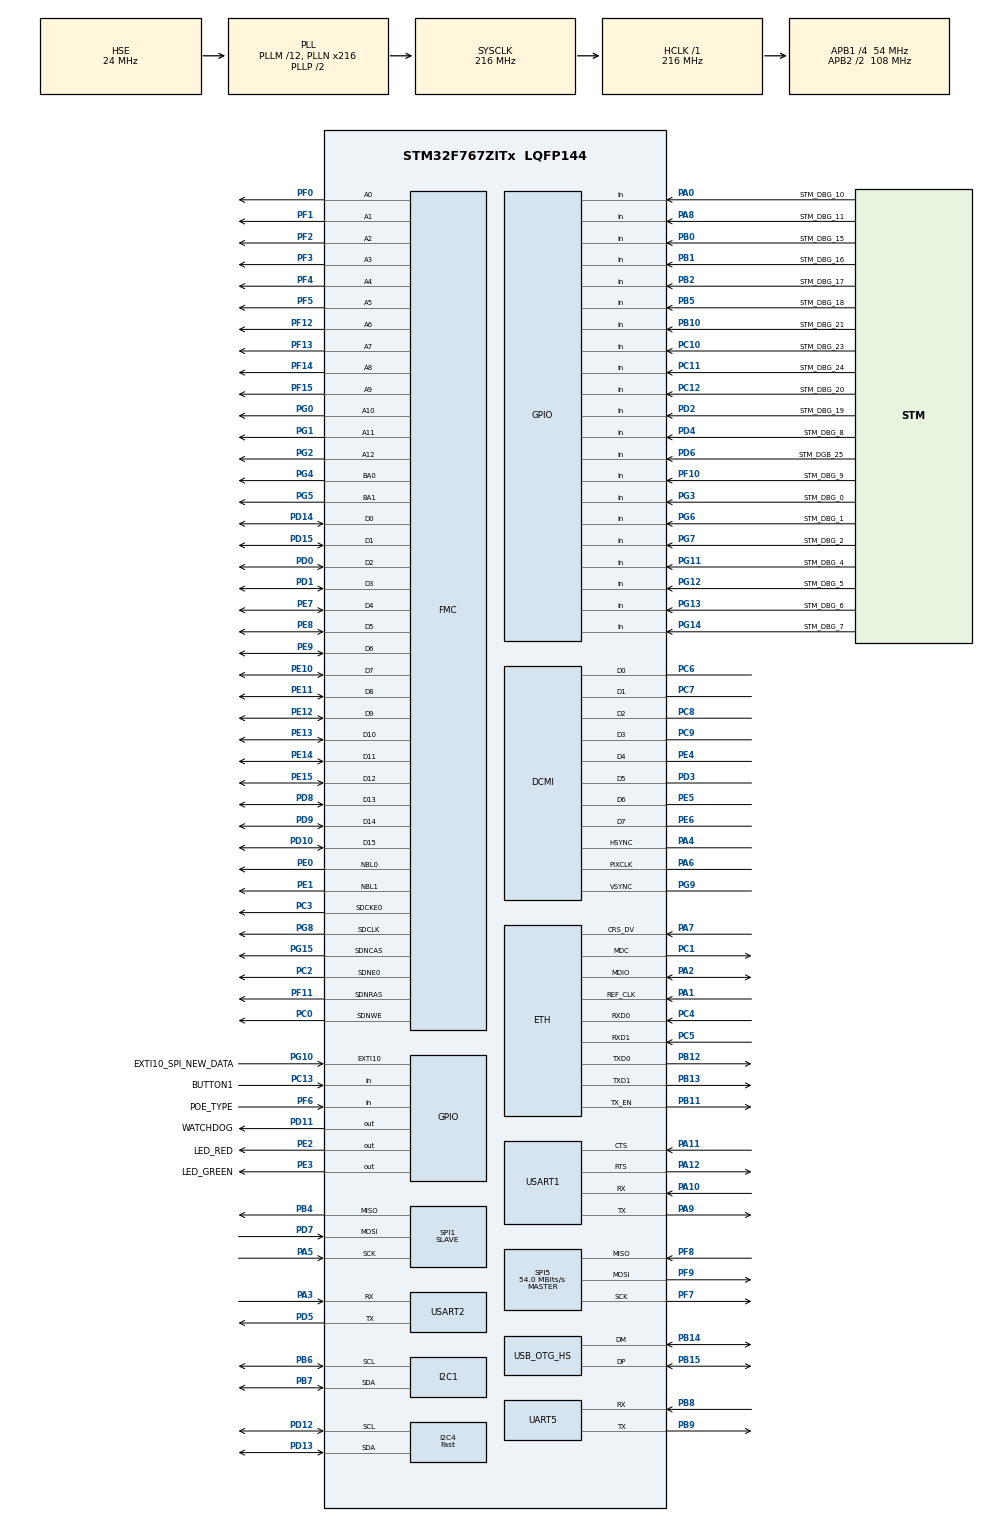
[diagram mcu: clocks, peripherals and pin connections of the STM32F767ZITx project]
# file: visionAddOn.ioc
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DCMI.CaptureRate=DCMI_CR_ALL_FRAME
DCMI.HSPolarity=DCMI_HSPOLARITY_LOW
DCMI.JPEGMode=DCMI_JPEG_DISABLE
DCMI.PCKPolarity=DCMI_PCKPOLARITY_RISING
DCMI.VSPolarity=DCMI_VSPOLARITY_LOW
Dma.DCMI.0.Direction=DMA_PERIPH_TO_MEMORY
Dma.DCMI.0.FIFOMode=DMA_FIFOMODE_DISABLE
Dma.DCMI.0.Instance=DMA2_Stream1
Dma.DCMI.0.MemDataAlignment=DMA_MDATAALIGN_WORD
Dma.DCMI.0.MemInc=DMA_MINC_ENABLE
Dma.DCMI.0.Mode=DMA_CIRCULAR
Dma.DCMI.0.PeriphDataAlignment=DMA_PDATAALIGN_WORD
Dma.DCMI.0.PeriphInc=DMA_PINC_DISABLE
Dma.DCMI.0.Priority=DMA_PRIORITY_HIGH
Dma.Request0=DCMI
Dma.Request1=USART2_RX
Dma.Request2=SPI1_RX
Dma.SPI1_RX.2.Direction=DMA_PERIPH_TO_MEMORY
Dma.SPI1_RX.2.FIFOMode=DMA_FIFOMODE_DISABLE
Dma.SPI1_RX.2.Instance=DMA2_Stream0
Dma.SPI1_RX.2.MemDataAlignment=DMA_MDATAALIGN_BYTE
Dma.SPI1_RX.2.MemInc=DMA_MINC_ENABLE
Dma.SPI1_RX.2.Mode=DMA_NORMAL
Dma.SPI1_RX.2.PeriphDataAlignment=DMA_PDATAALIGN_BYTE
Dma.SPI1_RX.2.PeriphInc=DMA_PINC_DISABLE
Dma.SPI1_RX.2.Priority=DMA_PRIORITY_MEDIUM
Dma.USART2_RX.1.Direction=DMA_PERIPH_TO_MEMORY
Dma.USART2_RX.1.FIFOMode=DMA_FIFOMODE_DISABLE
Dma.USART2_RX.1.Instance=DMA1_Stream5
Dma.USART2_RX.1.MemDataAlignment=DMA_MDATAALIGN_BYTE
Dma.USART2_RX.1.MemInc=DMA_MINC_ENABLE
Dma.USART2_RX.1.Mode=DMA_NORMAL
Dma.USART2_RX.1.PeriphDataAlignment=DMA_PDATAALIGN_BYTE
Dma.USART2_RX.1.PeriphInc=DMA_PINC_DISABLE
Dma.USART2_RX.1.Priority=DMA_PRIORITY_MEDIUM
ETH.MediaInterface=HAL_ETH_RMII_MODE
FMC.CASLatency1=FMC_SDRAM_CAS_LATENCY_3
FMC.ColumnBitsNumber1=FMC_SDRAM_COLUMN_BITS_NUM_9
FMC.ExitSelfRefreshDelay1=14
FMC.LoadToActiveDelay1=2
FMC.RCDDelay1=3
FMC.RPDelay1=3
FMC.RPDelay2=3
FMC.ReadBurst1=FMC_SDRAM_RBURST_ENABLE
FMC.ReadBurst2=FMC_SDRAM_RBURST_ENABLE
FMC.ReadPipeDelay1=FMC_SDRAM_RPIPE_DELAY_0
FMC.RowCycleDelay1=10
FMC.RowCycleDelay2=10
FMC.SDClockPeriod1=FMC_SDRAM_CLOCK_PERIOD_2
FMC.SDClockPeriod2=FMC_SDRAM_CLOCK_PERIOD_2
FREERTOS.Tasks01=networkTask,24,1024,StartNetworkTask,Default,NULL,Static,networkTaskBuffer,networkTaskControlBlock;blobDetectorTas,24,512,StartBlobDetectorTask,Default,NULL,Static,blobDetectorBuffer,blobDetectorControlBlock;statsTask,8,256,StartStatsTask,Default,NULL,Static,statsTaskBuffer,statsTaskControlBlock
FREERTOS.configCHECK_FOR_STACK_OVERFLOW=2
FREERTOS.configENABLE_FPU=1
FREERTOS.configGENERATE_RUN_TIME_STATS=1
FREERTOS.configRECORD_STACK_HIGH_ADDRESS=1
FREERTOS.configUSE_MALLOC_FAILED_HOOK=1
FREERTOS.configUSE_NEWLIB_REENTRANT=1
I2C1.Timing=0x20404768
I2C4.I2C_Speed_Mode=I2C_Fast
I2C4.Timing=0x6000030D
LWIP.BSP.number=1
LWIP.DEFAULT_RAW_RECVMBOX_SIZE=6
LWIP.DEFAULT_THREAD_STACKSIZE=1024
LWIP.GATEWAY_ADDRESS=010.000.000.001
LWIP.IP_ADDRESS=010.000.000.001
LWIP.LWIP_DHCP=0
LWIP.LWIP_DISABLE_TCP_SANITY_CHECKS=0
LWIP.LWIP_PERF=1
LWIP.LWIP_RAM_HEAP_POINTER=0x30004000
LWIP.LWIP_STATS=1
LWIP.MEMP_NUM_TCP_PCB=2
LWIP.MEMP_NUM_UDP_PCB=2
LWIP.MEM_SIZE=8192
LWIP.NETMASK_ADDRESS=255.255.255.000
LWIP.SLIPIF_THREAD_STACKSIZE=1024
LWIP.SYS_LIGHTWEIGHT_PROT=1
LWIP.TCPIP_THREAD_STACKSIZE=2048
LWIP.Version=v2.1.2_Cube
LWIP0.BSP.STBoard=false
LWIP0.BSP.api=BSP_COMPONENT_DRIVER
LWIP0.BSP.component=LAN8742
LWIP0.BSP.instance=LAN8742
LWIP0.BSP.name=Driver_PHY
LWIP0.BSP.semaphore=S_LAN8742
LWIP0.BSP.solution=LAN8742
Mcu.Family=STM32F7
Mcu.Name=STM32F767ZITx
Mcu.Package=LQFP144
NVIC.DCMI_IRQn=true\:5\:0\:false\:false\:true\:true\:true\:true\:true
NVIC.DMA1_Stream5_IRQn=true\:5\:0\:false\:false\:true\:true\:false\:true\:true
NVIC.DMA2_Stream0_IRQn=true\:5\:0\:false\:false\:true\:true\:false\:true\:true
NVIC.DMA2_Stream1_IRQn=true\:5\:0\:false\:false\:true\:true\:false\:true\:true
NVIC.ETH_IRQn=true\:5\:0\:false\:false\:true\:true\:false\:true\:true
NVIC.EXTI15_10_IRQn=true\:5\:0\:false\:false\:true\:true\:true\:true\:true
NVIC.PriorityGroup=NVIC_PRIORITYGROUP_4
NVIC.TIM1_UP_TIM10_IRQn=true\:15\:0\:false\:false\:true\:false\:false\:true\:true
NVIC.TimeBase=TIM1_UP_TIM10_IRQn
NVIC.TimeBaseIP=TIM1
NVIC.USART2_IRQn=true\:5\:0\:false\:false\:true\:true\:true\:true\:true
PA0/WKUP.GPIO_Label=STM_DBG_10
PA0/WKUP.Signal=GPIO_Input
PA1.Mode=RMII
PA1.Signal=ETH_REF_CLK
PA10.Mode=Asynchronous
PA10.Signal=USART1_RX
PA11.Mode=CTS_RTS
PA11.Signal=USART1_CTS
PA12.Mode=CTS_RTS
PA12.Signal=USART1_RTS
PA13.GPIO_Label=TMS
PA13.Mode=Serial_Wire
PA13.Signal=SYS_JTMS-SWDIO
PA14.GPIO_Label=TCK
PA14.Mode=Serial_Wire
PA14.Signal=SYS_JTCK-SWCLK
PA15.Signal=SYS_JTDI
PA2.Mode=RMII
PA2.Signal=ETH_MDIO
PA3.Mode=Asynchronous
PA3.Signal=USART2_RX
PA4.Mode=Slave_8_bits_External_Synchro
PA4.Signal=DCMI_HSYNC
PA5.Mode=Full_Duplex_Slave
PA5.Signal=SPI1_SCK
PA6.Mode=Slave_8_bits_External_Synchro
PA6.Signal=DCMI_PIXCLK
PA7.Mode=RMII
PA7.Signal=ETH_CRS_DV
PA8.GPIO_Label=STM_DBG_11
PA8.Signal=GPIO_Input
PA9.Mode=Asynchronous
PA9.Signal=USART1_TX
PB0.GPIO_Label=STM_DBG_15
PB0.Signal=GPIO_Input
PB1.GPIO_Label=STM_DBG_16
PB1.Signal=GPIO_Input
PB10.GPIO_Label=STM_DBG_21
PB10.Signal=GPIO_Input
PB11.Mode=RMII
PB11.Signal=ETH_TX_EN
PB12.Mode=RMII
PB12.Signal=ETH_TXD0
PB13.Mode=RMII
PB13.Signal=ETH_TXD1
PB14.Mode=Device_Only_FS
PB14.Signal=USB_OTG_HS_DM
PB15.Mode=Device_Only_FS
PB15.Signal=USB_OTG_HS_DP
PB2.GPIO_Label=STM_DBG_17
PB2.Signal=GPIO_Input
PB3.GPIO_Label=SWO
PB3.Signal=SYS_JTDO-SWO
PB4.Mode=Full_Duplex_Slave
PB4.Signal=SPI1_MISO
PB5.GPIO_Label=STM_DBG_18
PB5.Signal=GPIO_Input
PB6.Mode=I2C
PB6.Signal=I2C1_SCL
PB7.Mode=I2C
PB7.Signal=I2C1_SDA
PB8.Mode=Asynchronous
PB8.Signal=UART5_RX
PB9.Mode=Asynchronous
PB9.Signal=UART5_TX
PC0.Signal=FMC_SDNWE
PC1.Mode=RMII
PC1.Signal=ETH_MDC
PC10.GPIO_Label=STM_DBG_23
PC10.Signal=GPIO_Input
PC11.GPIO_Label=STM_DBG_24
PC11.Signal=GPIO_Input
PC12.GPIO_Label=STM_DBG_20
PC12.Signal=GPIO_Input
PC13.GPIO_Label=BUTTON1
PC13.Signal=GPIO_Input
PC14/OSC32_IN.Mode=LSE-External-Oscillator
PC14/OSC32_IN.Signal=RCC_OSC32_IN
PC15/OSC32_OUT.Mode=LSE-External-Oscillator
PC15/OSC32_OUT.Signal=RCC_OSC32_OUT
PC2.Mode=SdramChipSelect1_1
PC2.Signal=FMC_SDNE0
PC3.Mode=SdramChipSelect1_1
PC3.Signal=FMC_SDCKE0
PC4.Mode=RMII
PC4.Signal=ETH_RXD0
PC5.Mode=RMII
PC5.Signal=ETH_RXD1
PC6.Mode=Slave_8_bits_External_Synchro
PC6.Signal=DCMI_D0
PC7.Mode=Slave_8_bits_External_Synchro
PC7.Signal=DCMI_D1
PC8.Mode=Slave_8_bits_External_Synchro
PC8.Signal=DCMI_D2
PC9.Mode=Slave_8_bits_External_Synchro
PC9.Signal=DCMI_D3
PD0.Signal=FMC_D2_DA2
PD1.Signal=FMC_D3_DA3
PD10.Signal=FMC_D15_DA15
PD11.GPIO_Label=WATCHDOG
PD11.Signal=GPIO_Output
PD12.Mode=I2C
PD12.Signal=I2C4_SCL
PD13.Mode=I2C
PD13.Signal=I2C4_SDA
PD14.Signal=FMC_D0_DA0
PD15.Signal=FMC_D1_DA1
PD2.GPIO_Label=STM_DBG_19
PD2.Signal=GPIO_Input
PD3.Mode=Slave_8_bits_External_Synchro
PD3.Signal=DCMI_D5
PD4.GPIO_Label=STM_DBG_8
PD4.Signal=GPIO_Input
PD5.Mode=Asynchronous
PD5.Signal=USART2_TX
PD6.GPIO_Label=STM_DGB_25
PD6.Signal=GPIO_Input
PD7.Mode=Full_Duplex_Slave
PD7.Signal=SPI1_MOSI
PD8.Signal=FMC_D13_DA13
PD9.Signal=FMC_D14_DA14
PE0.Signal=FMC_NBL0
PE1.Signal=FMC_NBL1
PE10.Signal=FMC_D7_DA7
PE11.Signal=FMC_D8_DA8
PE12.Signal=FMC_D9_DA9
PE13.Signal=FMC_D10_DA10
PE14.Signal=FMC_D11_DA11
PE15.Signal=FMC_D12_DA12
PE2.GPIO_Label=LED_RED
PE2.Signal=GPIO_Output
PE3.GPIO_Label=LED_GREEN
PE3.Signal=GPIO_Output
PE4.Mode=Slave_8_bits_External_Synchro
PE4.Signal=DCMI_D4
PE5.Mode=Slave_8_bits_External_Synchro
PE5.Signal=DCMI_D6
PE6.Mode=Slave_8_bits_External_Synchro
PE6.Signal=DCMI_D7
PE7.Signal=FMC_D4_DA4
PE8.Signal=FMC_D5_DA5
PE9.Signal=FMC_D6_DA6
PF0.Signal=FMC_A0
PF1.Signal=FMC_A1
PF10.GPIO_Label=STM_DBG_9
PF10.Signal=GPIO_Input
PF11.Signal=FMC_SDNRAS
PF12.Signal=FMC_A6
PF13.Signal=FMC_A7
PF14.Signal=FMC_A8
PF15.Signal=FMC_A9
PF2.Signal=FMC_A2
PF3.Signal=FMC_A3
PF4.Signal=FMC_A4
PF5.Signal=FMC_A5
PF6.GPIO_Label=POE_TYPE
PF6.Signal=GPIO_Input
PF7.Mode=Full_Duplex_Master
PF7.Signal=SPI5_SCK
PF8.Mode=Full_Duplex_Master
PF8.Signal=SPI5_MISO
PF9.Mode=Full_Duplex_Master
PF9.Signal=SPI5_MOSI
PG0.Signal=FMC_A10
PG1.Signal=FMC_A11
PG10.GPIO_Label=EXTI10_SPI_NEW_DATA
PG10.Signal=GPXTI10
PG11.GPIO_Label=STM_DBG_4
PG11.Signal=GPIO_Input
PG12.GPIO_Label=STM_DBG_5
PG12.Signal=GPIO_Input
PG13.GPIO_Label=STM_DBG_6
PG13.Signal=GPIO_Input
PG14.GPIO_Label=STM_DBG_7
PG14.Signal=GPIO_Input
PG15.Signal=FMC_SDNCAS
PG2.Signal=FMC_A12
PG3.GPIO_Label=STM_DBG_0
PG3.Signal=GPIO_Input
PG4.Signal=FMC_A14_BA0
PG5.Signal=FMC_A15_BA1
PG6.GPIO_Label=STM_DBG_1
PG6.Signal=GPIO_Input
PG7.GPIO_Label=STM_DBG_2
PG7.Signal=GPIO_Input
PG8.Signal=FMC_SDCLK
PG9.Mode=Slave_8_bits_External_Synchro
PG9.Signal=DCMI_VSYNC
PH0/OSC_IN.Mode=HSE-External-Clock-Source
PH0/OSC_IN.Signal=RCC_OSC_IN
PH1/OSC_OUT.Mode=HSE-External-Clock-Source
PH1/OSC_OUT.Signal=RCC_OSC_OUT
ProjectManager.HeapSize=0x200
ProjectManager.StackSize=0x400
ProjectManager.TargetToolchain=CMake
RCC.48MHZClocksFreq_Value=24000000
RCC.AHBFreq_Value=216000000
RCC.APB1CLKDivider=RCC_HCLK_DIV4
RCC.APB1Freq_Value=54000000
RCC.APB1TimFreq_Value=108000000
RCC.APB2CLKDivider=RCC_HCLK_DIV2
RCC.APB2Freq_Value=108000000
RCC.APB2TimFreq_Value=216000000
RCC.CortexFreq_Value=216000000
RCC.HCLKFreq_Value=216000000
RCC.HSE_VALUE=24000000
RCC.HSI_VALUE=16000000
RCC.PLLM=12
RCC.PLLMUL=RCC_PLL_MUL9
RCC.PLLN=216
RCC.PLLQ=9
RCC.PRESCALERUSB=RCC_USBCLKSOURCE_PLL_DIV1_5
RCC.SYSCLKFreq_VALUE=216000000
RCC.SYSCLKSource=RCC_SYSCLKSOURCE_PLLCLK
RCC.SYSCLKSourceVirtual=RCC_SYSCLKSOURCE_PLLCLK
RCC.USBFreq_Value=48000000
RCC.VCOOutputFreq_Value=432000000
SH.FMC_A0.0=FMC_A0,13b-sda1
SH.FMC_A1.0=FMC_A1,13b-sda1
SH.FMC_A10.0=FMC_A10,13b-sda1
SH.FMC_A11.0=FMC_A11,13b-sda1
SH.FMC_A12.0=FMC_A12,13b-sda1
SH.FMC_A14_BA0.0=FMC_BA0,FourSdramBanks1
SH.FMC_A15_BA1.0=FMC_BA1,FourSdramBanks1
SH.FMC_A2.0=FMC_A2,13b-sda1
SH.FMC_A3.0=FMC_A3,13b-sda1
SH.FMC_A4.0=FMC_A4,13b-sda1
SH.FMC_A5.0=FMC_A5,13b-sda1
SH.FMC_A6.0=FMC_A6,13b-sda1
SH.FMC_A7.0=FMC_A7,13b-sda1
SH.FMC_A8.0=FMC_A8,13b-sda1
SH.FMC_A9.0=FMC_A9,13b-sda1
SH.FMC_D0_DA0.0=FMC_D0,sd-16b-d1
SH.FMC_D10_DA10.0=FMC_D10,sd-16b-d1
SH.FMC_D11_DA11.0=FMC_D11,sd-16b-d1
SH.FMC_D12_DA12.0=FMC_D12,sd-16b-d1
SH.FMC_D13_DA13.0=FMC_D13,sd-16b-d1
SH.FMC_D14_DA14.0=FMC_D14,sd-16b-d1
SH.FMC_D15_DA15.0=FMC_D15,sd-16b-d1
SH.FMC_D1_DA1.0=FMC_D1,sd-16b-d1
SH.FMC_D2_DA2.0=FMC_D2,sd-16b-d1
SH.FMC_D3_DA3.0=FMC_D3,sd-16b-d1
SH.FMC_D4_DA4.0=FMC_D4,sd-16b-d1
SH.FMC_D5_DA5.0=FMC_D5,sd-16b-d1
SH.FMC_D6_DA6.0=FMC_D6,sd-16b-d1
SH.FMC_D7_DA7.0=FMC_D7,sd-16b-d1
SH.FMC_D8_DA8.0=FMC_D8,sd-16b-d1
SH.FMC_D9_DA9.0=FMC_D9,sd-16b-d1
SH.FMC_NBL0.0=FMC_NBL0,Sd2ByteEnable1
SH.FMC_NBL1.0=FMC_NBL1,Sd2ByteEnable1
SH.FMC_SDCLK.0=FMC_SDCLK,13b-sda1
SH.FMC_SDNCAS.0=FMC_SDNCAS,13b-sda1
SH.FMC_SDNRAS.0=FMC_SDNRAS,13b-sda1
SH.FMC_SDNWE.0=FMC_SDNWE,13b-sda1
SPI1.CLKPhase=SPI_PHASE_2EDGE
SPI1.CLKPolarity=SPI_POLARITY_HIGH
SPI1.DataSize=SPI_DATASIZE_8BIT
SPI1.Direction=SPI_DIRECTION_2LINES
SPI1.Mode=SPI_MODE_SLAVE
SPI1.VirtualType=VM_SLAVE
SPI5.BaudRatePrescaler=SPI_BAUDRATEPRESCALER_2
SPI5.CalculateBaudRate=54.0 MBits/s
SPI5.Direction=SPI_DIRECTION_2LINES
SPI5.Mode=SPI_MODE_MASTER
SPI5.VirtualType=VM_MASTER
USART1.VirtualMode-Asynchronous=VM_ASYNC
USART2.VirtualMode-Asynchronous=VM_ASYNC
USB_OTG_HS.VirtualMode-Device_Only_FS=Device_Only_FS
VP_FREERTOS_VS_CMSIS_V2.Mode=CMSIS_V2
VP_LWIP_VS_Enabled.Mode=Enabled
VP_SYS_VS_tim1.Mode=TIM1
board=NUCLEO-F767ZI

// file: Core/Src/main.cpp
/* USER CODE BEGIN Header */
/**
  ******************************************************************************
  * @file           : main.c
  * @brief          : Main program body
  ******************************************************************************
  * @attention
  *
  * Copyright (c) 2025 STMicroelectronics.
  * All rights reserved.
  *
  * This software is licensed under terms that can be found in the LICENSE file
  * in the root directory of this software component.
  * If no LICENSE file comes with this software, it is provided AS-IS.
  *
  ******************************************************************************
  */
extern "C" {
/* USER CODE END Header */
#include "main.h"
#include "cmsis_os.h"
#include "dcmi.h"
#include "dma.h"
#include "i2c.h"
#include "lwip.h"
#include "spi.h"
#include "usart.h"
#include "usb_otg.h"
#include "gpio.h"
#include "fmc.h"

/* USER CODE BEGIN Includes */

#include <stdio.h>
/* USER CODE END Includes */

/* USER CODE BEGIN PD */
#define TEST_EXTERNAL_SDRAM
#define LWIP_DEBUG 1
#undef SOCKETS_DEBUG
#define SOCKETS_DEBUG LWIP_DBG_ON
#undef MEM_DEBUG
#define MEM_DEBUG LWIP_DBG_ON
#undef MEMP_DEBUG
#define MEMP_DEBUG LWIP_DBG_ON
/* USER CODE END PD */

void SystemClock_Config(void);
void MX_FREERTOS_Init(void);

/* USER CODE BEGIN 0 */
}
#include "AppBuilder.h"
#include "utils/swo.h"
#include "utils/Log.h"
#include "utils/constants.h"
#include "as4c16m16msa/sdram.h"
/* USER CODE END 0 */

int main(void)
{

  /* MCU Configuration--------------------------------------------------------*/

  /* Reset of all peripherals, Initializes the Flash interface and the Systick. */
  HAL_Init();

  /* Configure the system clock */
  SystemClock_Config();

  /* Initialize all configured peripherals */
  MX_GPIO_Init();
  MX_DMA_Init();
  MX_DCMI_Init();
  MX_FMC_Init();
  MX_USART1_UART_Init();
  MX_USART2_UART_Init();
  MX_I2C1_Init();
  MX_SPI1_Init();
  MX_I2C4_Init();
  MX_SPI5_Init();
  MX_UART5_Init();
  MX_USB_OTG_HS_PCD_Init();
  /* USER CODE BEGIN 2 */
  Log::registerTickKeeper([](void) -> uint32_t {return osKernelGetTickCount();});
  Log::setTickrate(TICKS_PER_MILLISECOND);
  Log::level(Log::Level::LOG_INFO);
  Log::info("[main] visionAddOn, commit %s", GIT_COMMIT_HASH);

  initSdram(&hsdram1);
#ifdef TEST_EXTERNAL_SDRAM
  Log::info("[main] testing sdram");
  uint32_t* externalSdramBase = (uint32_t*) EXTERNAL_SDRAM_BASE_ADDRESS;
  for(uint32_t offset = 0; offset < EXTERNAL_SDRAM_SIZE_WORDS; offset++) {
    if((EXTERNAL_SDRAM_BASE_ADDRESS + offset) > EXTERNAL_SDRAM_END_ADDRESS) {
      Log::error("[main] @ offset %#x: EXTERNAL_SDRAM_BASE_ADDRESS + offset = %#x, which is greater than EXTERNAL_SDRAM_END_ADDRESS (%#x)", offset, EXTERNAL_SDRAM_BASE_ADDRESS + offset, EXTERNAL_SDRAM_END_ADDRESS);
      Error_Handler();
    }
    externalSdramBase[offset] = offset;
    uint32_t offsetReadBack = externalSdramBase[offset];
    if(offset != offsetReadBack) {
      Log::error("[main] offset: %#x, offsetReadBack: %#x", offset, offsetReadBack);
      Error_Handler();
    }
  }
  Log::info("[main] sdram ok");
#endif // TEST_EXTERNAL_SDRAM

  /* USER CODE END 2 */

  /* Init scheduler */
  osKernelInitialize();

  /* Call init function for freertos objects (in cmsis_os2.c) */
  MX_FREERTOS_Init();

  /* Start scheduler */
  osKernelStart();

  /* We should never get here as control is now taken by the scheduler */

  /* Infinite loop */
  while (1)
  {

    /* USER CODE BEGIN 3 */
  } // extern C
// ignore the shitty RCC_OscInitStruct and RCC_ClkInitStruct initialization
#pragma GCC diagnostic push
#pragma GCC diagnostic ignored "-Wmissing-field-initializers"
  /* USER CODE END 3 */
}

void SystemClock_Config(void)
{
  RCC_OscInitTypeDef RCC_OscInitStruct = {0};
  RCC_ClkInitTypeDef RCC_ClkInitStruct = {0};

  /** Configure LSE Drive Capability
  */
  HAL_PWR_EnableBkUpAccess();

  /** Configure the main internal regulator output voltage
  */
  __HAL_RCC_PWR_CLK_ENABLE();
  __HAL_PWR_VOLTAGESCALING_CONFIG(PWR_REGULATOR_VOLTAGE_SCALE1);

  /** Initializes the RCC Oscillators according to the specified parameters
  * in the RCC_OscInitTypeDef structure.
  */
  RCC_OscInitStruct.OscillatorType = RCC_OSCILLATORTYPE_HSE;
  RCC_OscInitStruct.HSEState = RCC_HSE_BYPASS;
  RCC_OscInitStruct.PLL.PLLState = RCC_PLL_ON;
  RCC_OscInitStruct.PLL.PLLSource = RCC_PLLSOURCE_HSE;
  RCC_OscInitStruct.PLL.PLLM = 12;
  RCC_OscInitStruct.PLL.PLLN = 216;
  RCC_OscInitStruct.PLL.PLLP = RCC_PLLP_DIV2;
  RCC_OscInitStruct.PLL.PLLQ = 9;
  RCC_OscInitStruct.PLL.PLLR = 2;
  if (HAL_RCC_OscConfig(&RCC_OscInitStruct) != HAL_OK)
  {
    Error_Handler();
  }

  /** Activate the Over-Drive mode
  */
  if (HAL_PWREx_EnableOverDrive() != HAL_OK)
  {
    Error_Handler();
  }

  /** Initializes the CPU, AHB and APB buses clocks
  */
  RCC_ClkInitStruct.ClockType = RCC_CLOCKTYPE_HCLK|RCC_CLOCKTYPE_SYSCLK
                              |RCC_CLOCKTYPE_PCLK1|RCC_CLOCKTYPE_PCLK2;
  RCC_ClkInitStruct.SYSCLKSource = RCC_SYSCLKSOURCE_PLLCLK;
  RCC_ClkInitStruct.AHBCLKDivider = RCC_SYSCLK_DIV1;
  RCC_ClkInitStruct.APB1CLKDivider = RCC_HCLK_DIV4;
  RCC_ClkInitStruct.APB2CLKDivider = RCC_HCLK_DIV2;

  if (HAL_RCC_ClockConfig(&RCC_ClkInitStruct, FLASH_LATENCY_7) != HAL_OK)
  {
    Error_Handler();
  }
}

/* USER CODE BEGIN 4 */
#pragma GCC diagnostic pop // "-Wmissing-field-initializers"
/* USER CODE END 4 */

void HAL_TIM_PeriodElapsedCallback(TIM_HandleTypeDef *htim)
{
  if (htim->Instance == TIM1) {
    HAL_IncTick();
  }
}

void Error_Handler(void)
{
  /* USER CODE BEGIN Error_Handler_Debug */
  /* User can add his own implementation to report the HAL error return state */
  __disable_irq();
  log_error("[Error_Handler]");
  abort();
  /* USER CODE END Error_Handler_Debug */
}

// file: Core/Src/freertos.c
/* USER CODE BEGIN Header */
/**
  ******************************************************************************
  * File Name          : freertos.c
  * Description        : Code for freertos applications
  ******************************************************************************
  * @attention
  *
  * Copyright (c) 2025 STMicroelectronics.
  * All rights reserved.
  *
  * This software is licensed under terms that can be found in the LICENSE file
  * in the root directory of this software component.
  * If no LICENSE file comes with this software, it is provided AS-IS.
  *
  ******************************************************************************
  */
/* USER CODE END Header */

#include "FreeRTOS.h"
#include "task.h"
#include "main.h"
#include "cmsis_os.h"

/* USER CODE BEGIN Includes */
#include "c_app_builder.h"
#include "lwip.h"
#include "utils/c_log.h"
#include "utils/allocator.h"
#include "utils/constants.h"
#include "ethernetif.h"
#include <stdio.h>
/* USER CODE END Includes */

typedef StaticTask_t osStaticThreadDef_t;

/* Definitions for networkTask */
osThreadId_t networkTaskHandle;
uint32_t networkTaskBuffer[ 1024 ];
osStaticThreadDef_t networkTaskControlBlock;
const osThreadAttr_t networkTask_attributes = {
  .name = "networkTask",
  .cb_mem = &networkTaskControlBlock,
  .cb_size = sizeof(networkTaskControlBlock),
  .stack_mem = &networkTaskBuffer[0],
  .stack_size = sizeof(networkTaskBuffer),
  .priority = (osPriority_t) osPriorityNormal,
};
/* Definitions for blobDetectorTas */
osThreadId_t blobDetectorTasHandle;
uint32_t blobDetectorBuffer[ 512 ];
osStaticThreadDef_t blobDetectorControlBlock;
const osThreadAttr_t blobDetectorTas_attributes = {
  .name = "blobDetectorTas",
  .cb_mem = &blobDetectorControlBlock,
  .cb_size = sizeof(blobDetectorControlBlock),
  .stack_mem = &blobDetectorBuffer[0],
  .stack_size = sizeof(blobDetectorBuffer),
  .priority = (osPriority_t) osPriorityNormal,
};
/* Definitions for statsTask */
osThreadId_t statsTaskHandle;
uint32_t statsTaskBuffer[ 256 ];
osStaticThreadDef_t statsTaskControlBlock;
const osThreadAttr_t statsTask_attributes = {
  .name = "statsTask",
  .cb_mem = &statsTaskControlBlock,
  .cb_size = sizeof(statsTaskControlBlock),
  .stack_mem = &statsTaskBuffer[0],
  .stack_size = sizeof(statsTaskBuffer),
  .priority = (osPriority_t) osPriorityLow,
};

void StartNetworkTask(void *argument);
void StartBlobDetectorTask(void *argument);
void StartStatsTask(void *argument);

extern void MX_LWIP_Init(void);
void MX_FREERTOS_Init(void); /* (MISRA C 2004 rule 8.1) */

/* Hook prototypes */
void configureTimerForRunTimeStats(void);
unsigned long getRunTimeCounterValue(void);
void vApplicationStackOverflowHook(xTaskHandle xTask, signed char *pcTaskName);
void vApplicationMallocFailedHook(void);

/* USER CODE BEGIN 1 */
/* Functions needed when configGENERATE_RUN_TIME_STATS is on */
__weak void configureTimerForRunTimeStats(void)
{

}

__weak unsigned long getRunTimeCounterValue(void)
{
return 0;
}
/* USER CODE END 1 */

/* USER CODE BEGIN 4 */
void vApplicationStackOverflowHook(xTaskHandle xTask, signed char *pcTaskName)
{
   /* Run time stack overflow checking is performed if
   configCHECK_FOR_STACK_OVERFLOW is defined to 1 or 2. This hook function is
   called if a stack overflow is detected. */
   (void) xTask;
   log_error("[vApplicationStackOverflowHook] stack overflow of task %s ", pcTaskName);
   Error_Handler();
}
/* USER CODE END 4 */

/* USER CODE BEGIN 5 */
void vApplicationMallocFailedHook(void)
{
   /* vApplicationMallocFailedHook() will only be called if
   configUSE_MALLOC_FAILED_HOOK is set to 1 in FreeRTOSConfig.h. It is a hook
   function that will get called if a call to pvPortMalloc() fails.
   pvPortMalloc() is called internally by the kernel whenever a task, queue,
   timer or semaphore is created. It is also called by various parts of the
   demo application. If heap_1.c or heap_2.c are used, then the size of the
   heap available to pvPortMalloc() is defined by configTOTAL_HEAP_SIZE in
   FreeRTOSConfig.h, and the xPortGetFreeHeapSize() API function can be used
   to query the size of free heap space that remains (although it does not
   provide information on how the remaining heap might be fragmented). */
   log_error("[vApplicationMallocFailedHook]");
   Error_Handler();
}
/* USER CODE END 5 */

void MX_FREERTOS_Init(void) {
  /* USER CODE BEGIN Init */
  MX_LWIP_Register_locals_to_app_builder();
  /* USER CODE END Init */

  /* USER CODE BEGIN RTOS_TIMERS */
  app_build();
  persisted_mac = app_fetch_mac_address_from_storage();

  /* USER CODE END RTOS_TIMERS */

  /* Create the thread(s) */
  /* creation of networkTask */
  networkTaskHandle = osThreadNew(StartNetworkTask, NULL, &networkTask_attributes);

  /* creation of blobDetectorTas */
  blobDetectorTasHandle = osThreadNew(StartBlobDetectorTask, NULL, &blobDetectorTas_attributes);

  /* creation of statsTask */
  statsTaskHandle = osThreadNew(StartStatsTask, NULL, &statsTask_attributes);

}

void StartNetworkTask(void *argument)
{
  /* init code for LWIP */
  MX_LWIP_Init();
  /* USER CODE BEGIN StartNetworkTask */
  (void)argument;
  log_info("[StartNetworkTask] locking heap");
  lock_heap();
  log_info("[StartNetworkTask] init command handler");
  app_init_command_handler();
  for(;;)
  {
    app_run_command_handler(); // blocking!
    osDelay(1);
  }
  /* USER CODE END StartNetworkTask */
}

void StartBlobDetectorTask(void *argument)
{
  /* USER CODE BEGIN StartBlobDetectorTask */
  (void)argument;
  log_info("[StartBlobDetectorTask] init camera");
  app_init_camera();
  app_init_network_config();
  /* Infinite loop */
  for(;;)
  {
    app_run_blob_receiver();
    osDelay(1);
  }
  /* USER CODE END StartBlobDetectorTask */
}

void StartStatsTask(void *argument)
{
  /* USER CODE BEGIN StartStatsTask */
  (void)argument;
  /* Infinite loop */
  for(;;)
  {
    //app_run_network_stats();
    osDelay(100);
  }
  /* USER CODE END StartStatsTask */
}
